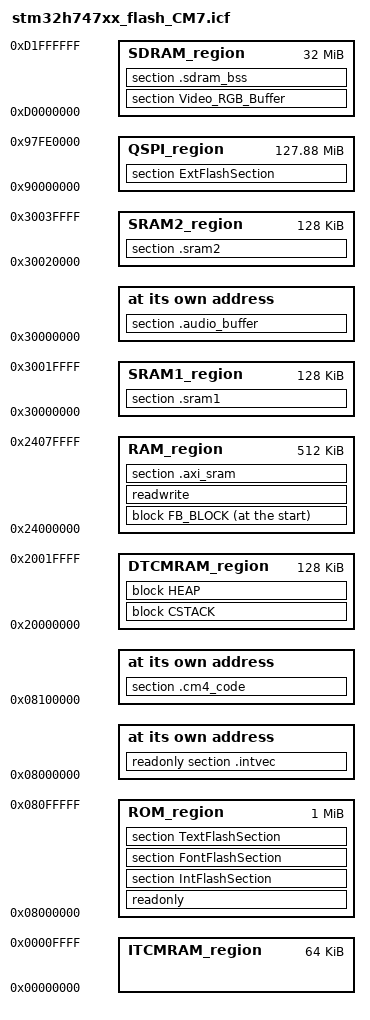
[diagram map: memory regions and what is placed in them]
/*###ICF### Section handled by ICF editor, don't touch! ****/
/*-Editor annotation file-*/
/* IcfEditorFile="$TOOLKIT_DIR$\config\ide\IcfEditor\cortex_v1_0.xml" */
/*-Specials-*/
define symbol __ICFEDIT_intvec_start__ = 0x08000000;
/*-Memory Regions-*/
define symbol __ICFEDIT_region_ROM_start__     = 0x08000000;
define symbol __ICFEDIT_region_ROM_end__       = 0x080FFFFF;
define symbol __ICFEDIT_region_RAM_start__     = 0x24000000;
define symbol __ICFEDIT_region_RAM_end__       = 0x2407FFFF;
define symbol __ICFEDIT_region_ITCMRAM_start__ = 0x00000000;
define symbol __ICFEDIT_region_ITCMRAM_end__   = 0x0000FFFF;
define symbol __ICFEDIT_region_DTCMRAM_start__ = 0x20000000;
define symbol __ICFEDIT_region_DTCMRAM_end__   = 0x2001FFFF;
define symbol __ICFEDIT_region_SRAM1_start__   = 0x30000000;
define symbol __ICFEDIT_region_SRAM1_end__     = 0x3001FFFF;
define symbol __ICFEDIT_region_SRAM2_start__   = 0x30020000;
define symbol __ICFEDIT_region_SRAM2_end__     = 0x3003FFFF;
/*-Sizes-*/
define symbol __ICFEDIT_size_cstack__ = 0x2000;  /* 8KB — IAR reported 96% used at 4KB */
define symbol __ICFEDIT_size_heap__   = 0x1000;
/**** End of ICF editor section. ###ICF###*/

/*-Quad-SPI Memory Regions-*/
define symbol __ICFEDIT_region_SDRAM_start__   = 0xD0000000;
define symbol __ICFEDIT_region_SDRAM_end__     = 0xD1FFFFFF;
define symbol __ICFEDIT_region_QSPI_start__    = 0x90000000;
define symbol __ICFEDIT_region_QSPI_end__      = 0x97FE0000;

define memory mem with size = 4G;
define region ROM_region      = mem:[from __ICFEDIT_region_ROM_start__   to __ICFEDIT_region_ROM_end__];
define region RAM_region      = mem:[from __ICFEDIT_region_RAM_start__   to __ICFEDIT_region_RAM_end__];
define region ITCMRAM_region  = mem:[from __ICFEDIT_region_ITCMRAM_start__ to __ICFEDIT_region_ITCMRAM_end__];
define region DTCMRAM_region  = mem:[from __ICFEDIT_region_DTCMRAM_start__ to __ICFEDIT_region_DTCMRAM_end__];
define region SRAM1_region    = mem:[from __ICFEDIT_region_SRAM1_start__ to __ICFEDIT_region_SRAM1_end__];
define region SRAM2_region    = mem:[from __ICFEDIT_region_SRAM2_start__ to __ICFEDIT_region_SRAM2_end__];

define region SDRAM_region    = mem:[from __ICFEDIT_region_SDRAM_start__      to __ICFEDIT_region_SDRAM_end__];
define region QSPI_region     = mem:[from __ICFEDIT_region_QSPI_start__    to __ICFEDIT_region_QSPI_end__];

define block CSTACK    with alignment = 8, size = __ICFEDIT_size_cstack__   { };
define block HEAP      with alignment = 8, size = __ICFEDIT_size_heap__     { };


initialize by copy { readwrite };
do not initialize  { section .noinit, section Video_RGB_Buffer, section TouchGFX_Framebuffer,
                     section .sdram_bss,
                     section .audio_buffer };
/* AUDIO BISECT 2026-05-10: .freertos_heap section temporarily removed —
 * heap_4 uses its internal xHeap (lands in AXI .bss) per
 * configAPPLICATION_ALLOCATED_HEAP=0 in FreeRTOSConfig.h. */

place at address mem:__ICFEDIT_intvec_start__ { readonly section .intvec };
place at address mem:0x08100000 { section .cm4_code };

place in ROM_region   { readonly, section IntFlashSection, section FontFlashSection, section TextFlashSection };

/* ═══════════════════════════════════════════════════════════════════════════
 * STM32H747 POWER DOMAIN ARCHITECTURE
 * ═══════════════════════════════════════════════════════════════════════════
 *
 *  The H747 has three independent power domains. Each domain has its own:
 *  clock gate, voltage regulator, and can enter low-power independently.
 *  DMA controllers are domain-bound — they can only reach RAM in their
 *  own domain or via the AHB bus matrix crossbar (with constraints below).
 *
 *  ┌──────────────────────────────────────────────────────────────────────┐
 *  │  D1 — Core Domain (always-on while M7 runs)                        │
 *  │  CPU: Cortex-M7 @ 400 MHz                                          │
 *  │  DMA: MDMA (Memory-to-Memory DMA, can reach ALL domains)           │
 *  │  DMA: DMA2D (2D graphics blitter, D1 only)                         │
 *  │  Peripherals: JPEG decoder, OCTOSPI, FMC (SDRAM/QSPI controller)  │
 *  │  RAM owned by D1:                                                   │
 *  │    • Flash   0x08000000  (1 MB internal, bus: AXIM)                │
 *  │    • ITCM    0x00000000  (64 KB, M7 instruction cache — NO DMA)    │
 *  │    • DTCM    0x20000000  (128 KB, zero-wait M7 data — NO DMA)      │
 *  │    • AXI SRAM 0x24000000 (512 KB, D1 AHB bus — DMA1/2/MDMA OK)    │
 *  └──────────────────────────────────────────────────────────────────────┘
 *            │ AHB bus matrix crossbar (M7 can reach D2/D3 RAM)
 *  ┌──────────────────────────────────────────────────────────────────────┐
 *  │  D2 — Peripheral Domain (active when any D2 peripheral runs)       │
 *  │  CPU: Cortex-M4 @ 200 MHz (not used in this project — firmware     │
 *  │       for CM4 is a stub; only CM7 runs application code)           │
 *  │  DMA: DMA1 (audio pipeline: DFSDM→SRAM1)                          │
 *  │  DMA: DMA2 (SD card: SDMMC1 IDMA → AXI SRAM bounce buffer)        │
 *  │  Peripherals: DFSDM1, SDMMC1/2, SAI1/2/3, SPI, I2C, USART, USB   │
 *  │  RAM owned by D2:                                                   │
 *  │    • SRAM1  0x30000000  (128 KB — DMA1/DMA2/MDMA accessible)       │
 *  │    • SRAM2  0x30020000  (128 KB — DMA1/DMA2/MDMA accessible)       │
 *  │    • SRAM3  0x30040000  (32 KB  — DMA1/DMA2/MDMA accessible)       │
 *  │  Rule: DMA1/DMA2 can access D1 AXI SRAM and D2 SRAM via crossbar  │
 *  │         but CANNOT reach D3 SRAM directly.                         │
 *  └──────────────────────────────────────────────────────────────────────┘
 *            │ internal silicon bridge (SAI4→DFSDM1, D3→D2 data path)
 *  ┌──────────────────────────────────────────────────────────────────────┐
 *  │  D3 — Low-Power Domain (can stay alive when D1+D2 are stopped)     │
 *  │  CPU: none (no processor in D3)                                    │
 *  │  DMA: BDMA — can ONLY reach D3 SRAM (0x38000000). Cannot touch     │
 *  │         D1 AXI or D2 SRAM at all.                                  │
 *  │  Peripherals: SAI4 (PDM mic clock+data), LPTIM, RTC, LPUART,      │
 *  │               ADC3, DAC, I2C4, SPI6                                │
 *  │  RAM owned by D3:                                                   │
 *  │    • SRAM4  0x38000000  (64 KB — only BDMA and M7 can access)      │
 *  │    • Backup 0x38800000  (4 KB  — battery-backed, RTC data)         │
 *  │  Rule: if SAI4 were DMA'd directly, buffer MUST be at 0x38000000.  │
 *  │   This project uses SAI4→DFSDM1 internal bridge instead — SAI4     │
 *  │   forwards PDM bits to D2 DFSDM1 via silicon routing, so BDMA      │
 *  │   and D3 SRAM are NOT needed. D3 SRAM4 is unused in this project.  │
 *  └──────────────────────────────────────────────────────────────────────┘
 *
 * ═══════════════════════════════════════════════════════════════════════════
 * MEMORY MAP — Per-Region: Domain, DMA Rules, Owner Tasks, Buffers
 * ═══════════════════════════════════════════════════════════════════════════
 *
 *  ┌─────────────────────────────────────────────────────────────────────┐
 *  │ INTERNAL FLASH — D1 domain — 0x08000000..0x080FFFFF (1 MB)        │
 *  │   DMA reach: MDMA (read), M7 AXIM bus (fetch/read)                │
 *  │   • Code, read-only data, vector table, font/text flash sections   │
 *  │   • CM4 stub at 0x08100000 (fixed offset for dual-core boot)      │
 *  └─────────────────────────────────────────────────────────────────────┘
 *
 *  ┌─────────────────────────────────────────────────────────────────────┐
 *  │ ITCM — D1 domain — 0x00000000..0x0000FFFF (64 KB)                 │
 *  │   DMA reach: NONE — tightly coupled to M7 instruction bus only     │
 *  │   Not used in this project (code runs from Flash/AXI SRAM).        │
 *  └─────────────────────────────────────────────────────────────────────┘
 *
 *  ┌─────────────────────────────────────────────────────────────────────┐
 *  │ DTCM — D1 domain — 0x20000000..0x2001FFFF (128 KB)                │
 *  │   DMA reach: NONE — tightly coupled to M7 data bus (DTCMRAM)      │
 *  │   Zero wait-state: fastest possible CPU reads/writes               │
 *  │                                                                     │
 *  │   Owner: M7 core interrupt/main stack + heap                       │
 *  │     • CSTACK (8 KB) — all ISRs and FreeRTOS scheduler run here    │
 *  │     • HEAP   (1 KB) — unused (no dynamic allocation in project)    │
 *  │                                                                     │
 *  │   RULE: Never place any DMA buffer here — DMA cannot see DTCM.    │
 *  └─────────────────────────────────────────────────────────────────────┘
 *
 *  ┌─────────────────────────────────────────────────────────────────────┐
 *  │ AXI SRAM — D1 domain — 0x24000000..0x2407FFFF (512 KB)            │
 *  │   DMA reach: DMA1, DMA2 (via AHB bus crossbar), MDMA              │
 *  │   M7 D-Cache: ENABLED — DMA writes require cache invalidation      │
 *  │                                                                     │
 *  │   Owner: ALL FreeRTOS tasks (default .bss / .data placement)       │
 *  │                                                                     │
 *  │   VoiceRecTask (D1 ↔ D2 data flow — records audio):               │
 *  │     • Task stack, s_dmaQueue (DFSDM ISR → task signalling)        │
 *  │     • s_pcmBounce[16384] — SDMMC IDMA reads WAV payload from here │
 *  │     • g_State, g_SampleCount, g_DmaCallCount (shared globals)     │
 *  │                                                                     │
 *  │   SDWriteTask (D1 AXI ← D2 SRAM2 via memcpy bounce):             │
 *  │     • Task stack, xVoiceQueue, FatFS ff.c work area               │
 *  │     • WAV header built on stack, written via SDMMC IDMA           │
 *  │                                                                     │
 *  │   RTTLogTask (pure D1):                                            │
 *  │     • Task stack, xLogQueue (receives strings from all tasks)      │
 *  │                                                                     │
 *  │   TouchGFX / DisplayTask (D1 ↔ SDRAM for framebuffers):           │
 *  │     • Task stack, TouchGFX engine state, JPEG temp decode buffer   │
 *  │                                                                     │
 *  │   FreeRTOS kernel:                                                 │
 *  │     • TCBs, ready/delayed/suspended lists, timer wheel, queues    │
 *  └─────────────────────────────────────────────────────────────────────┘
 *
 *  ┌─────────────────────────────────────────────────────────────────────┐
 *  │ D2 SRAM1 — D2 domain — 0x30000000..0x3001FFFF (128 KB)            │
 *  │   DMA reach: DMA1 (write) ✓  DMA2 ✓  MDMA ✓                      │
 *  │              BDMA ✗ (D3 DMA cannot cross into D2)                  │
 *  │   M7 D-Cache: ENABLED (default MPU — no override for this region)  │
 *  │     → SCB_InvalidateDCache_by_Addr() REQUIRED before CPU reads     │
 *  │       data that DMA1 just wrote (voice_recorder.c drain loop)      │
 *  │                                                                     │
 *  │   Owner: VoiceRecTask read + DMA1 write (DFSDM audio pipeline)    │
 *  │                                                                     │
 *  │     • g_DfsdmBuf[32] int32_t (128 bytes) at 0x30000000            │
 *  │       DMA1_Stream1 fills this circularly from DFSDM1_Filter0       │
 *  │       DFSDM writes 24-bit sign-extended values into 32-bit words   │
 *  │       VoiceRecTask calls SCB_Invalidate → StoreDmaChunk → >>8      │
 *  │       Placed via: #pragma location = 0x30000000                    │
 *  │                                                                     │
 *  │   Why D2 SRAM (not D1 AXI)?                                        │
 *  │     DMA1 lives in D2 and can reach both D1 and D2 RAM.            │
 *  │     Placing the DFSDM buffer in D2 SRAM1 avoids sharing the AXI   │
 *  │     bus with SDMMC1 IDMA during simultaneous SD writes.            │
 *  └─────────────────────────────────────────────────────────────────────┘
 *
 *  ┌─────────────────────────────────────────────────────────────────────┐
 *  │ D2 SRAM2 — D2 domain — 0x30020000..0x3003FFFF (128 KB)            │
 *  │   DMA reach: DMA1 ✓  DMA2 ✓  MDMA ✓                               │
 *  │              BDMA ✗  SDMMC IDMA: use AXI SRAM bounce (safer)       │
 *  │   M7 D-Cache: ENABLED                                              │
 *  │                                                                     │
 *  │   Owner: VoiceRecTask (write) → SDWriteTask (read via bounce buf)  │
 *  │                                                                     │
 *  │     • g_AudioBuf[48000] int16_t (96 KB) at 0x30020000             │
 *  │       VoiceRecTask accumulates PCM samples here during recording   │
 *  │       StoreDmaChunk: src32[i]>>8 → int16, stored by CPU in D2     │
 *  │       SDWriteTask: memcpy chunk → s_pcmBounce (AXI) → SDMMC IDMA  │
 *  │       Placed via: #pragma location = 0x30020000                    │
 *  │                                                                     │
 *  │   Why not D1 AXI?                                                  │
 *  │     Original placement was SDRAM (.sdram_bss) — SDMMC IDMA caused  │
 *  │     RXOVERR because FMC auto-refresh (every 7.8 µs) blocked the    │
 *  │     AHB3 bus. D2 SRAM2 uses a separate bounce buffer to decouple.  │
 *  └─────────────────────────────────────────────────────────────────────┘
 *
 *  ┌─────────────────────────────────────────────────────────────────────┐
 *  │ D3 SRAM4 — D3 domain — 0x38000000..0x3800FFFF (64 KB)  [UNUSED]   │
 *  │   DMA reach: BDMA only — strictly D3-local                         │
 *  │              M7 can read/write via AHB slave port                  │
 *  │              DMA1/DMA2/MDMA: cannot access this region             │
 *  │                                                                     │
 *  │   Relevant history: SAI4 in BDMA mode would DMA PDM bits here.    │
 *  │   This project uses SAI4→DFSDM1 internal silicon bridge instead.  │
 *  │   SAI4 (D3 peripheral) forwards PDM data directly into DFSDM1     │
 *  │   (D2 peripheral) without any DMA or CPU involvement.             │
 *  │   D3 SRAM4 is therefore unused and not defined in this linker file.│
 *  └─────────────────────────────────────────────────────────────────────┘
 *
 *  ┌─────────────────────────────────────────────────────────────────────┐
 *  │ SDRAM — external — 0xD0000000..0xD1FFFFFF (32 MB)                 │
 *  │   Connected via FMC (AHB3 bus, D1 domain)                         │
 *  │   DMA reach: MDMA ✓  DMA1/DMA2: not recommended (AHB3 latency)    │
 *  │                                                                     │
 *  │   Owner: DisplayTask / TouchGFX engine                             │
 *  │     • TouchGFX_Framebuffer — double-buffered RGB565 display output │
 *  │     • Video_RGB_Buffer — video frame decode staging area           │
 *  │     • .sdram_bss — large TouchGFX lookup tables, asset data        │
 *  └─────────────────────────────────────────────────────────────────────┘
 *
 *  ┌─────────────────────────────────────────────────────────────────────┐
 *  │ QSPI Flash — external — 0x90000000..0x97FE0000                    │
 *  │   Connected via OCTOSPI (AHB3 bus, D1 domain)                     │
 *  │   Read-only at runtime (memory-mapped XIP access)                  │
 *  │   • ExtFlashSection — pre-computed UI assets, font bitmaps         │
 *  └─────────────────────────────────────────────────────────────────────┘
 * ═══════════════════════════════════════════════════════════════════════════ */

/* AXI SRAM D1 — default home for all task stacks, FreeRTOS, globals */

/* TouchGFX Partial Framebuffer (800×120×3 = 288,000 B strip buffer) anchored
 * at the start of AXI SRAM (0x24000000). LTDC reads from here only — FMC bus
 * stays free for JPEG/CPU/MDMA in SDRAM. Eliminates FUIF contention.
 * Per AN4861 §2/§9 + AN4891 system architecture. 32-byte aligned for DMA2D. */
define block FB_BLOCK with alignment = 32 { section TouchGFX_Framebuffer };
place at start of RAM_region { block FB_BLOCK };

place in RAM_region   { readwrite };

/* Stack/Heap in DTCM — fastest M7 access, no DMA contention */
place in DTCMRAM_region { block CSTACK, block HEAP };

/* D2 SRAM1 — DFSDM DMA buffer (g_DfsdmBuf at 0x30000000, 128 bytes)
 * Placed via #pragma location in voice_recorder.c — section anchors the region. */
place at address mem:0x30000000 { section .audio_buffer };

/* AUDIO BISECT 2026-05-10: heap relocation REVERTED. heap_4 uses internal
 * xHeap[] (lands in AXI .bss). Original placement preserved as comment:
 *   place in SRAM1_region { section .freertos_heap };
 */

/* D2 SRAM2 — g_AudioBuf (0x30020000, 96 KB) placed via #pragma location.
 * No section needed — absolute address placement bypasses the linker region.
 * SRAM2_region is defined above so the linker knows this address space exists
 * and can catch any accidental overlap with future allocations. */

/* ── Named section anchors for Rule #3 (Section Attribution) ──────────────
 * Per CLAUDE.md Rule #3: any static buffer that must live in a specific
 * domain MUST use __attribute__((section(...))) so its placement is a
 * compile-time property of the source. These section names are the
 * authoritative list — using any other name will fail link-time.
 *
 *   section .axi_sram  → D1 AXI SRAM (default .bss target; explicit tag)
 *   section .sram1     → D2 SRAM1   (DMA1/DMA2 reachable, e.g. DFSDM extras)
 *   section .sram2     → D2 SRAM2   (DMA1/DMA2 reachable, e.g. queues/audio)
 *
 * Note: existing absolute-address placements (#pragma location = 0x30000000
 * for g_DfsdmBuf, 0x30020000 for g_AudioBuf) keep working unchanged — they
 * bypass these section regions by design. Use named sections for everything
 * that doesn't need a literal hardcoded address. */
place in RAM_region    { section .axi_sram };
place in SRAM1_region  { section .sram1 };
place in SRAM2_region  { section .sram2 };

place in QSPI_region   { section ExtFlashSection };
place in SDRAM_region  { section Video_RGB_Buffer,
                         section .sdram_bss };
